# CPSW_SS register map
Vendor: Texas Instruments
Peripheral module from a debugger description file (folder am437x).
Registers are 32-bit, access per field, no defined reset value unless marked. A register's access mark holds for its fields unless they carry their own. Offsets are as the file gives them; lines under a group give offsets from that group; [hi:lo] are bit positions; {n}, {i} and the like mark numbered series; 'fields as' and 'values as' point back to an identical list; <NAME> marks a mode.

## CPSW_SS
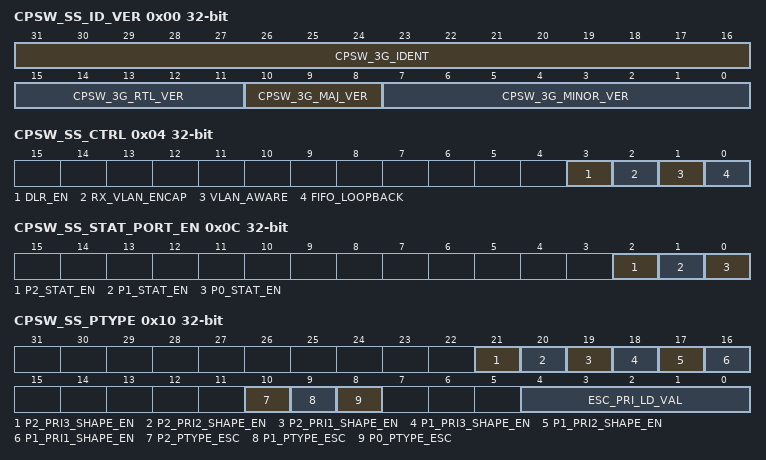
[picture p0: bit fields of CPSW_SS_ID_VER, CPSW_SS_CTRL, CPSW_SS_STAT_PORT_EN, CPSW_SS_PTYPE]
0x00 CPSW_SS_ID_VER ro — ID VERSION REGISTER
  [31:16] CPSW_3G_IDENT — 3G Identification Value
  [15:11] CPSW_3G_RTL_VER — 3G RTL Version Value
  [10:8] CPSW_3G_MAJ_VER — 3G Major Version Value
  [7:0] CPSW_3G_MINOR_VER — 3G Minor Version Value
0x04 CPSW_SS_CTRL — SWITCH CONTROL REGISTER
  [3] DLR_EN rw — DLR enable
    1=en_2_0x1 (DLR is enabled. DLR packets be moved to destination port transmit queue priority 3 and will be separated out onto dlr_cpdma_ch when packet is to egress on port 0.); 0=en_1_0x0 (DLR is disabled. DLR packets will not be moved to queue priority 3 and will not be separated out onto dlr_cpdma_ch.)
  [2] RX_VLAN_ENCAP rw — Port 0 VLAN Encapsulation (egress):
    1=en_2_0x1 (Port 2 receive packets (from 3G) are VLAN encapsulated.); 0=en_1_0x0 (Port 2 receive packets (from 3G) are not VLAN encapsulated.)
  [1] VLAN_AWARE rw — VLAN Aware Mode:
    1=en_2_0x1 (3G is in the VLAN aware mode.); 0=en_1_0x0 (3G is in the VLAN unaware mode.)
  [0] FIFO_LOOPBACK rw — FIFO Loopback Mode
    1=en_2_0x1 (FIFO Loopback mode enabled. Each packet received is turned around and sent out on the same port's transmit path. Port 2 receive is fixed on channel zero. The RXSOFOVERRUN statistic will increment for every packet sent in FIFO loopback mode.); 0=en_1_0x0 (Loopback is disabled)
0x08 CPSW_SS_SOFT_RESET — SOFT RESET REGISTER
  [0] SOFT_RESET rw — Software reset - Writing a one to this bit causes the 3G logic to be reset. [[br]]After writing a one to this bit, it may be polled to determine if the reset has occurred. [[br]]If a one is read, the reset has not yet occurred. [[br]]If a zero is read then reset has occurred. [[br]]
0x0C CPSW_SS_STAT_PORT_EN — STATISTICS PORT ENABLE REGISTER
  [2] P2_STAT_EN rw — Port 2 (GMII2 and Port 2 FIFO) Statistics Enable
    1=en_2_0x1 (Port 2 statistics are enabled.); 0=en_1_0x0 (Port 2 statistics are not enabled.)
  [1] P1_STAT_EN rw — Port 1 (GMII1 and Port 1 FIFO) Statistics Enable
    1=en_2_0x1 (Port 1 statistics are enabled.); 0=en_1_0x0 (Port 1 statistics are not enabled.)
  [0] P0_STAT_EN rw — Port 0 Statistics Enable. [[br]]FIFO overruns (SOFOVERRUNS) are the only port 0 statistics that are enabled to be kept. [[br]]
    1=en_2_0x1 (Port 0 statistics are enabled.); 0=en_1_0x0 (Port 0 statistics are not enabled.)
0x10 CPSW_SS_PTYPE — TRANSMIT PRIORITY TYPE REGISTER
  [21] P2_PRI3_SHAPE_EN rw — Port 2 Queue Priority 3 Transmit Shape Enable - If there is only one shaping queue then it must be priority 3. [[br]]
  [20] P2_PRI2_SHAPE_EN rw — Port 2 Queue Priority 2 Transmit Shape Enable - If there are two shaping queues then they must be priorities 3 and 2. [[br]]
  [19] P2_PRI1_SHAPE_EN rw — Port 2 Queue Priority 1 Transmit Shape Enable - If there are three shaping queues all three bits should be set. [[br]]
  [18] P1_PRI3_SHAPE_EN rw — Port 1 Queue Priority 3 Transmit Shape Enable - If there is only one shaping queue then it must be priority 3. [[br]]
  [17] P1_PRI2_SHAPE_EN rw — Port 1 Queue Priority 2 Transmit Shape Enable- If there are two shaping queues then they must be priorities 3 and 2. [[br]]
  [16] P1_PRI1_SHAPE_EN rw — Port 1 Queue Priority 1 Transmit Shape Enable- If there are three shaping queues all three bits should be set. [[br]]
  [10] P2_PTYPE_ESC rw — Port 2 Priority Type Escalate
    1=en_2_0x1 (Port 2 priority type escalate Escalate should not be used with queue shaping.); 0=en_1_0x0 (Port 2 priority type fixed)
  [9] P1_PTYPE_ESC rw — Port 1 Priority Type Escalate
    1=en_2_0x1 (Port 1 priority type escalate Escalate should not be used with queue shaping.); 0=en_1_0x0 (Port 1 priority type fixed)
  [8] P0_PTYPE_ESC rw — Port 0 Priority Type Escalate
    1=en_2_0x1 (Port 0 priority type escalate Escalate should not be used with queue shaping.); 0=en_1_0x0 (Port 0 priority type fixed)
  [4:0] ESC_PRI_LD_VAL rw — Escalate Priority Load Value When a port is in escalate priority, this is the number of higher priority packets sent before the next lower priority is allowed to send a packet. [[br]]Escalate priority allows lower priority packets to be sent at a fixed rate relative to the next higher priority. [[br]]
0x14 CPSW_SS_SOFT_IDLE — SOFTWARE IDLE
  [0] SOFT_IDLE rw — Software Idle - Setting this bit causes the switch fabric to stop forwarding packets at the next start of packet. [[br]]
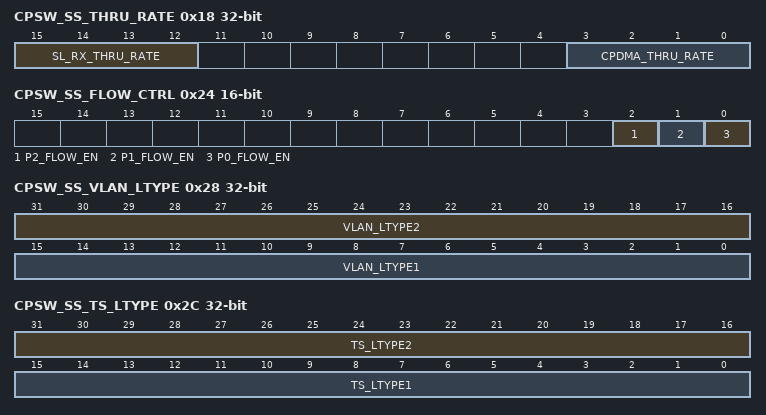
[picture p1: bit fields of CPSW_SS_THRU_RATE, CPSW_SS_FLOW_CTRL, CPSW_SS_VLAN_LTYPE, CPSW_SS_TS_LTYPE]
0x18 CPSW_SS_THRU_RATE — THROUGHPUT RATE
  [15:12] SL_RX_THRU_RATE rw — CPGMAC_SL Switch FIFO receive through rate. [[br]]This register value is the maximum throughput of the ethernet ports to the crossbar SCR. [[br]]The default is one [[br]]8-byte word for every 3 CLK periods maximum. [[br]]
  [3:0] CPDMA_THRU_RATE rw — CPDMA Switch FIFO receive through rate. [[br]]This register value is the maximum throughput of the CPDMA host port to the crossbar SCR. [[br]]The default is one [[br]]8-byte word for every 3 CLK periods maximum. [[br]]
0x1C CPSW_SS_GAP_THRESH — CPGMAC_SL SHORT GAP THRESHOLD
  [4:0] GAP_THRESH rw — CPGMAC_SL Short Gap Threshold - This is the CPGMAC_SL associated FIFO transmit block usage value for triggering TX_SHORT_GAP. [[br]]
0x20 CPSW_SS_TX_START_WDS — TRANSMIT START WORDS
  [10:0] TX_START_WDS rw — FIFO Packet Transmit (egress) Start Words. [[br]]This value is the number of required packet words in the transmit FIFO before the packet egress will begin. [[br]]This value is non-zero to preclude underrun. [[br]]Decimal 32 is the recommended value. [[br]]It should not be increased unnecessairly to prevent adding to the switch latency. [[br]]
0x24 CPSW_SS_FLOW_CTRL 16-bit — FLOW CONTROL
  [2] P2_FLOW_EN rw — Port 2 Receive flow control enable
  [1] P1_FLOW_EN rw — Port 1 Receive flow control enable
  [0] P0_FLOW_EN rw — Port 0 Receive flow control enable
0x28 CPSW_SS_VLAN_LTYPE rw — LTYPE1 AND LTYPE 2 REGISTER
  [31:16] VLAN_LTYPE2 — Time Sync VLAN LTYPE2 This VLAN LTYPE value is used for tx and rx. [[br]]This is the inner VLAN if both are present. [[br]]
  [15:0] VLAN_LTYPE1 — Time Sync VLAN LTYPE1 This VLAN LTYPE value is used for tx and rx. [[br]]This is the outer VLAN if both are present. [[br]]
0x2C CPSW_SS_TS_LTYPE rw — VLAN_LTYPE1 AND VLAN_LTYPE2 REGISTER
  [31:16] TS_LTYPE2 — Time Sync LTYPE2 This is an Ethertype value to match for tx and rx time sync packets.
  [15:0] TS_LTYPE1 — Time Sync LTYPE1 This is an ethertype value to match for tx and rx time sync packets.
0x30 CPSW_SS_DLR_LTYPE 16-bit rw — DLR LTYPE REGISTER
  [15:0] DLR_LTYPE
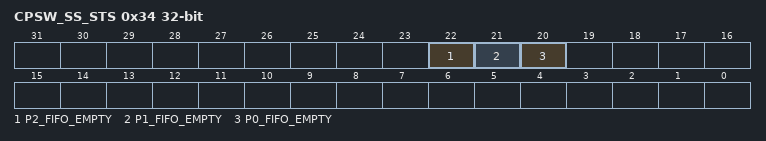
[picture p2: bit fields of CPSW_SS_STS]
0x34 CPSW_SS_STS access not given
  [22] P2_FIFO_EMPTY — Port 2 Transmit FIFO Empty
    1=en_2_0x1 (The port 2 transmit FIFO is empty. The packet can still be in transmission, but when set this bit indicates that there are no full packets in the transmit FIFO.); 0=en_1_0x0 (There are packet(s) in the port 2 transmit FIFO.)
  [21] P1_FIFO_EMPTY — Port 1 Transmit FIFO Empty
    1=en_2_0x1 (The port 1 transmit FIFO is empty. The packet can still be in transmission, but when set this bit indicates that there are no full packets in the transmit FIFO.); 0=en_1_0x0 (There are packet(s) in the port 1 transmit FIFO.)
  [20] P0_FIFO_EMPTY — Port 0 Transmit FIFO Empty
    values as P2_FIFO_EMPTY
